# STM32G553 register map
File version: 2.0.0
CPU: CM33 r0p4, little endian, MPU, FPU, 4 interrupt priority bits
Registers are 32-bit, read-write, reset 0x0 unless marked. A register's access mark holds for its fields unless they carry their own. Offsets are from the block's base; [hi:lo] are bit positions; lines under a group give offsets from that group; 'fields as' and 'values as' point back to an identical list.

## FLASH — FLASH register block
Base 0x40022000
Same registers: FLASH_S 0x50022000
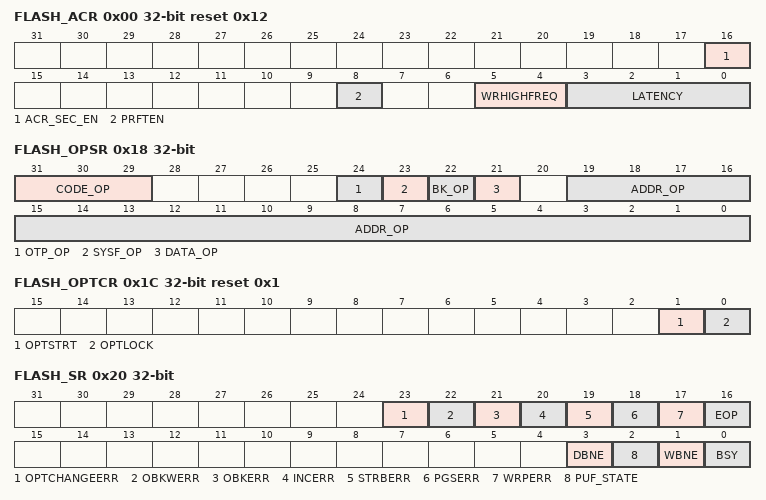
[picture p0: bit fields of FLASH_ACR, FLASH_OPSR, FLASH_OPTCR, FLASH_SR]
0x00 FLASH_ACR reset 0x12 — FLASH access control register
  [16] ACR_SEC_EN — This bit restricts the contents of the FLASH_ACR from nonsecure write access.
    0=all nonsecure access to FLASH_ACR permitted; 1=nonsecure write access to FLASH_ACR results in illegal access error. The register is read only for nonsecure code.
  [8] PRFTEN — Prefetch enable. When bit value is modified, user must read back ACR register to be sure PRFTEN has been taken into account.
    0=prefetch disabled; 1=prefetch enabled when latency is at least one wait state
  [5:4] WRHIGHFREQ — Flash signal delay
  [3:0] LATENCY — Read latency
    0=zero wait states used to read a word from nonvolatile memory; 1=one wait state used to read a word from nonvolatile memory; 2=two wait states used to read a word from nonvolatile memory; 7=seven wait states used to read a word from nonvolatile memory; 15=15 wait states used to read a word from nonvolatile memory
0x04 FLASH_KEYR wo — FLASH nonsecure key register
  [31:0] KEY — Non-volatile memory nonsecure configuration access unlock key
0x08 FLASH_SKEYR wo — FLASH secure key register
  [31:0] KEY — Non-volatile memory secure configuration access unlock key
0x0C FLASH_OPTKEYR wo — FLASH option key register
  [31:0] KEY — FLASH option bytes control access unlock key
0x10 FLASH_OBKKEYR wo — FLASH nonsecure OBK key register
  [31:0] KEY — FLASH nonsecure option bytes keys control access unlock key
0x14 FLASH_SOBKKEYR wo — FLASH secure OBK key register
  [31:0] KEY — FLASH secure option bytes keys control access unlock key
0x18 FLASH_OPSR ro reset not defined — FLASH operation status register
  [31:29] CODE_OP — Flash memory operation code
    0=No flash operation on going during previous reset; 1=Single write operation interrupted; 2=OBK alternate page erase; 3=Page erase operation interrupted; 4=Bank erase operation interrupted; 5=Mass erase operation interrupted; 6=Option change operation interrupted; 7=OBK swap page request
  [24] OTP_OP — OTP operation interrupted
  [23] SYSF_OP — Operation in system flash memory interrupted
  [22] BK_OP — Interrupted operation bank
  [21] DATA_OP — Flash high-cycle data area operation interrupted
  [19:0] ADDR_OP — Interrupted operation address
0x1C FLASH_OPTCR reset 0x1 — FLASH option control register
  [1] OPTSTRT — Option byte start change option configuration bit
  [0] OPTLOCK — FLASH_OPTCR lock option configuration bit
    0=FLASH_OPTCR register unlocked; 1=FLASH_OPTCR register locked
0x20 FLASH_SR ro (reset mask 0xFFFFFFF0) — FLASH nonsecure status register
  [23] OPTCHANGEERR — Option byte change error flag
    0=no option byte change errors occurred; 1=one or more errors occurred during an option byte change operation
  [22] OBKWERR — OBK write error flag
    0=no OBK write error occurred; 1=an OBK write error occurred
  [21] OBKERR — OBK general error flag
    0=no OBK general error occurred; 1=an OBK general error occurred
  [20] INCERR — inconsistency error flag
    0=no inconsistency error occurs; 1=a inconsistency error occurs
  [19] STRBERR — strobe error flag
    0=no strobe error occurred; 1=a strobe error occurred
  [18] PGSERR — programming sequence error flag
    0=no sequence error occurred; 1=a sequence error occurred
  [17] WRPERR — write protection error flag
    0=no write protection error occurred; 1=a write protection error occurred
  [16] EOP — end of operation flag
    0=no operation completed; 1=a operation completed
  [3] DBNE — data buffer not empty flag
    0=data buffer not used; 1=data buffer used, wait
  [2] PUF_STATE — PUF readiness
    0=PUF is not ready. Retry PUF_LAUNCH; 1=PUF is ready for use
  [1] WBNE — write buffer not empty flag
    0=write buffer empty or full; 1=write buffer waiting data to complete
  [0] BSY — busy flag
    0=no programming, erase or option byte change operation being executed; 1=programming, erase or option byte change operation being executed
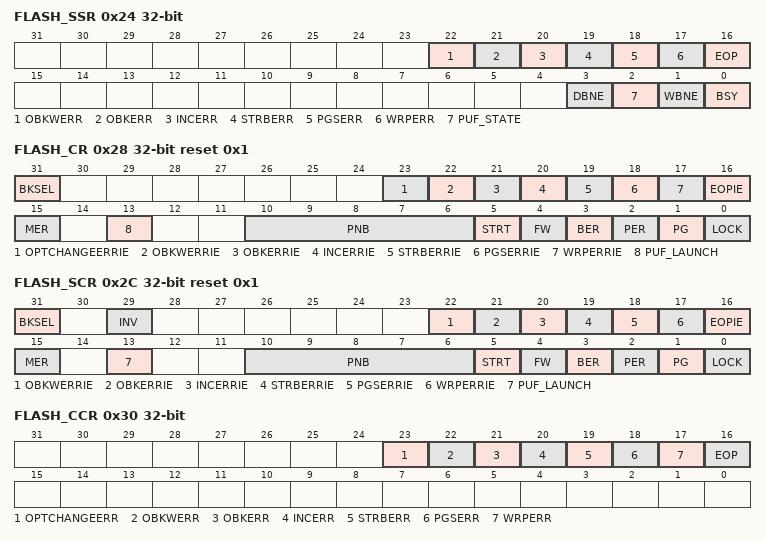
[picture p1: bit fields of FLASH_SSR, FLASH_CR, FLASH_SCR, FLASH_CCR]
0x24 FLASH_SSR ro (reset mask 0xFFFFFFF0) — FLASH secure status register
  [22] OBKWERR — OBK write error flag
    0=no OBK write error occurred; 1=an OBK write error occurred
  [21] OBKERR — OBK general error flag
    values as FLASH_SR.OBKERR
  [20] INCERR — inconsistency error flag
    0=no inconsistency error occurred; 1=a inconsistency error occurred
  [19] STRBERR — strobe error flag
    0=no strobe error occurred; 1=a strobe error occurred
  [18] PGSERR — programming sequence error flag
    0=no sequence error occurred; 1=a sequence error occurred
  [17] WRPERR — write protection error flag
    values as FLASH_SR.WRPERR
  [16] EOP — end of operation flag
    0=no operation completed; 1=a operation completed
  [3] DBNE — data buffer not empty flag
    0=data buffer not used; 1=data buffer used, wait
  [2] PUF_STATE — PUF readiness
    0=PUF is not ready. Retry PUF_LAUNCH; 1=PUF is ready for use
  [1] WBNE — write buffer not empty flag
    values as FLASH_SR.WBNE
  [0] BSY — busy flag
    values as FLASH_SR.BSY
0x28 FLASH_CR reset 0x1 — FLASH nonsecure control register
  [31] BKSEL — Bank selector bit
    0=Bank1 is selected for Bank erase / page erase / interrupt enable; 1=Bank2 is selected for BER / PER
  [23] OPTCHANGEERRIE — Option byte change error interrupt enable bit
    0=no interrupt is generated when an error occurs during an option byte change; 1=an interrupt is generated when and error occurs during an option byte change
  [22] OBKWERRIE — OBK write error interrupt enable bit
    0=no interrupt is generated on OBK write error; 1=an interrupt is generated on OBK write error
  [21] OBKERRIE — OBK general error interrupt enable bit
    0=no interrupt is generated on OBK general access error; 1=an interrupt is generated on OBK general access error
  [20] INCERRIE — inconsistency error interrupt enable bit
    0=no interrupt generated when a inconsistency error occurs; 1=interrupt generated when a inconsistency error occurs
  [19] STRBERRIE — strobe error interrupt enable bit
    0=no interrupt generated when a strobe error occurs; 1=interrupt generated when strobe error occurs
  [18] PGSERRIE — programming sequence error interrupt enable bit
    0=no interrupt generated when a sequence error occurs; 1=interrupt generated when sequence error occurs
  [17] WRPERRIE — write protection error interrupt enable bit
    0=no interrupt generated when a protection error occurs; 1=interrupt generated when a protection error occurs
  [16] EOPIE — end of operation interrupt control bit
    0=no interrupt generated at the end of operation; 1=interrupt enabled when at the end of operation
  [15] MER — Mass erase request
    0=mass erase not requested; 1=mass erase requested
  [13] PUF_LAUNCH — PUF preparation start control bit
  [10:6] PNB — page erase selection number
    0=Page 0 selected; 1=Page 1 selected; 31=Page 31 selected
  [5] STRT — erase start control bit
  [4] FW — write forcing control bit
  [3] BER — erase request
    0=bank erase not requested; 1=bank erase requested
  [2] PER — page erase request
    0=page erase not requested; 1=page erase requested
  [1] PG — programming control bit
    0=programming disabled; 1=programming enabled
  [0] LOCK — configuration lock bit
    0=FLASH_CR register unlocked; 1=FLASH_CR register locked
0x2C FLASH_SCR reset 0x1 — FLASH secure control register
  [31] BKSEL — bank selector bit
    values as FLASH_CR.BKSEL
  [29] INV — Flash memory security state invert.
  [22] OBKWERRIE — OBK write error interrupt enable bit
    values as FLASH_CR.OBKWERRIE
  [21] OBKERRIE — OBK general error interrupt enable bit
    values as FLASH_CR.OBKERRIE
  [20] INCERRIE — inconsistency error interrupt enable bit
    values as FLASH_CR.INCERRIE
  [19] STRBERRIE — strobe error interrupt enable bit
    values as FLASH_CR.STRBERRIE
  [18] PGSERRIE — programming sequence error interrupt enable bit
    values as FLASH_CR.PGSERRIE
  [17] WRPERRIE — write protection error interrupt enable bit
    values as FLASH_CR.WRPERRIE
  [16] EOPIE — end of operation interrupt control bit
    values as FLASH_CR.EOPIE
  [15] MER — mass erase request
    0=mass erase not requested; 1=mass erase requested
  [13] PUF_LAUNCH — PUF preparation start control bit
  [10:6] PNB — page erase selection number
    0=Page 0 selected; 1=Page 1 selected; 31=Page 31 selected
  [5] STRT — erase start control bit
  [4] FW — write forcing control bit
  [3] BER — erase request
    0=bank erase not requested; 1=bank erase requested
  [2] PER — page erase request
    0=page erase not requested; 1=page erase requested
  [1] PG — programming control bit
    0=programming disabled; 1=programming enabled
  [0] LOCK — configuration lock bit
    0=FLASH_SCR register unlocked; 1=FLASH_SCR register locked
0x30 FLASH_CCR wo — FLASH nonsecure clear control register
  [23] OPTCHANGEERR — Clear the flag corresponding flag in FLASH_SR by writing this bit.
  [22] OBKWERR — OBKWERR flag clear bit.
  [21] OBKERR — OBKERR flag clear bit.
  [20] INCERR — INCERR flag clear bit
  [19] STRBERR — STRBERR flag clear bit
  [18] PGSERR — PGSERR flag clear bit
  [17] WRPERR — WRPERR flag clear bit
  [16] EOP — EOP flag clear bit
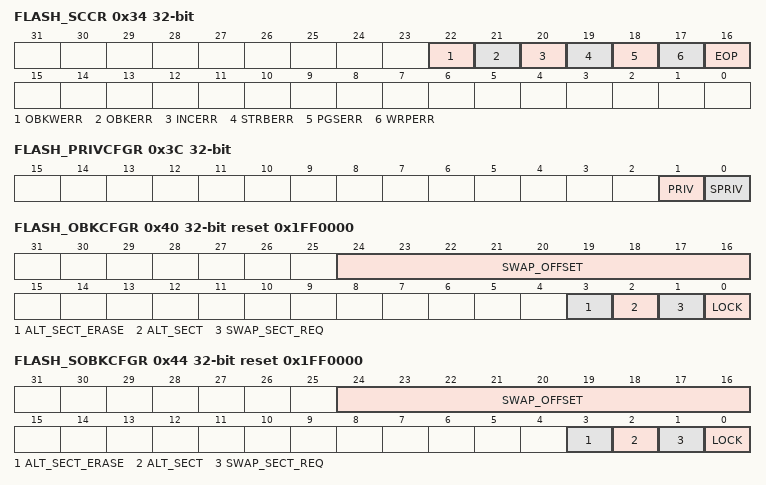
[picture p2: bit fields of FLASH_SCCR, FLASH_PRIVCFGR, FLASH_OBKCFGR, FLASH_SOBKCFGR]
0x34 FLASH_SCCR wo — FLASH secure clear control register
  [22] OBKWERR — OBKWERR flag clear bit
  [21] OBKERR — OBKWERR flag clear bit
  [20] INCERR — INCERR flag clear bit
  [19] STRBERR — STRBERR flag clear bit
  [18] PGSERR — PGSERR flag clear bit
  [17] WRPERR — WRPERR flag clear bit
  [16] EOP — EOP flag clear bit
0x3C FLASH_PRIVCFGR — FLASH privilege configuration register
  [1] PRIV — privilege attribute for non secure registers
    0=access to non secure registers is always granted; 1=access to non secure registers is denied in case of unprivileged access
  [0] SPRIV — privilege attribute for secure registers
    0=access to secure registers is always granted; 1=access to secure registers is denied in case of unprivileged access
0x40 FLASH_OBKCFGR reset 0x1FF0000 — FLASH nonsecure OBK configuration register
  [24:16] SWAP_OFFSET — Key index (offset /16 bits) pointing for next swap.
    0=means that no OBK is copied from current to alternate OBK page during SWAP operation; 0x1FF=means that all OBK data (511) are copied
  [3] ALT_SECT_ERASE — alternate page erase bit
    0=do not touch OBK page; 1=erase the alternate OBK page
  [2] ALT_SECT — alternate page bit
    0=current OBK page is mapped to OBK address range for access; 1=alternate OBK page is mapped to OBK address range for access
  [1] SWAP_SECT_REQ — OBK swap page request bit
    0=no swap requested; 1=launch the page swap
  [0] LOCK — OBKCFGR lock option configuration bit
    0=FLASH_OBKCFGR register unlocked; 1=FLASH_OBKCFGR register locked
0x44 FLASH_SOBKCFGR reset 0x1FF0000 — FLASH secure OBK configuration register
  [24:16] SWAP_OFFSET — key index (offset /16 bits) pointing for next swap.
    0=no OBK is copied from current to alternate OBK page during SWAP operation; 1=only the first OBK data (128 bits) are copied from current to alternate OBK page; 2=the two first OBK data are copied; 0x1FF=that the 511 first OBK data are copied
  [3] ALT_SECT_ERASE — alternate page erase bit
    0=do not touch OBK page; 1=erase the alternate OBK page
  [2] ALT_SECT — alternate page bit
    values as FLASH_OBKCFGR.ALT_SECT
  [1] SWAP_SECT_REQ — OBK swap page request bit
    0=no swap requested; 1=launch the page swap
  [0] LOCK — OBKCFGR lock option configuration bit
    values as FLASH_OBKCFGR.LOCK
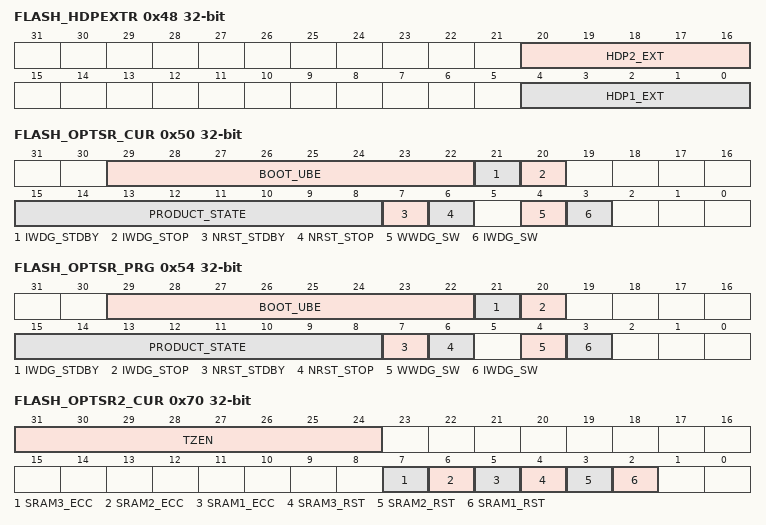
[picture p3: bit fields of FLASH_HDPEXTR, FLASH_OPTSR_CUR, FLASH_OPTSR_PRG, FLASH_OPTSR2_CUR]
0x48 FLASH_HDPEXTR — FLASH HDP extension register
  [20:16] HDP2_EXT — HDP area extension in 8Kbytes pages in Bank2. Extension is added after the END page (included).
  [4:0] HDP1_EXT — HDP area extension in 8Kbytes pages in Bank1. Extension is added after the END page (included).
0x50 FLASH_OPTSR_CUR ro reset not defined — FLASH option status register
  [29:22] BOOT_UBE — Available only on cryptography enabled devices.
    195=ST-iRoT (system flash) selected; 180=OEM-iRoT (user flash) selected. In Open PRODUCT_STATE this value selects bootloader. Default value.
  [21] IWDG_STDBY — IWDG Standby mode freeze option status bit
    0=Independent watchdog 1 frozen in Standby mode; 1=Independent watchdog 1 keep running in Standby mode
  [20] IWDG_STOP — IWDG Stop mode freeze option status bit
    0=Independent watchdog 1 frozen in system Stop mode; 1=Independent watchdog 1 keep running in system Stop mode
  [15:8] PRODUCT_STATE — Life state code (based on Hamming 8,4). See in Section201.6.11: Product state transitions.
  [7] NRST_STDBY — Core domain Standby entry reset option status bit
    0=a reset is generated when entering Standby mode on core domain; 1=no reset generated when entering Standby mode on core domain
  [6] NRST_STOP — Core domain Stop entry reset option status bit
    0=a reset is generated when entering Stop mode on core domain; 1=no reset generated when entering Stop mode on core domain
  [4] WWDG_SW — WWDG control mode option status bit
    0=WWDG watchdog is controlled by hardware; 1=WWDG watchdog is controlled by software
  [3] IWDG_SW — IWDG control mode option status bit
    0=IWDG watchdog is controlled by hardware; 1=IWDG watchdog is controlled by software
0x54 FLASH_OPTSR_PRG reset not defined — FLASH option status register
  [29:22] BOOT_UBE — Available only on cryptography enabled devices.
    195=ST-iRoT (system flash) selected; 180=OEM-iRoT (user flash) selected
  [21] IWDG_STDBY — IWDG Standby mode freeze option status bit
    0=Independent watchdog frozen in Standby mode; 1=Independent watchdog keep running in Standby mode
  [20] IWDG_STOP — IWDG Stop mode freeze option status bit
    0=Independent watchdog frozen in system Stop mode; 1=Independent watchdog keep running in system Stop mode
  [15:8] PRODUCT_STATE — Life state code (based on Hamming 8,4). See in Section201.6.11: Product state transitions.
  [7] NRST_STDBY — Core domain Standby entry reset option configuration bit
    values as FLASH_OPTSR_CUR.NRST_STDBY
  [6] NRST_STOP — Core domain Stop entry reset option configuration bit
    values as FLASH_OPTSR_CUR.NRST_STOP
  [4] WWDG_SW — WWDG control mode option configuration bit
    values as FLASH_OPTSR_CUR.WWDG_SW
  [3] IWDG_SW — IWDG control mode option configuration bit
    values as FLASH_OPTSR_CUR.IWDG_SW
0x60 FLASH_EPOCHR_CUR ro reset not defined — FLASH nonsecure EPOCH register
  [23:0] EPOCH — Non-volatile nonsecure EPOCH counter
0x64 FLASH_EPOCHR_PRG reset not defined — FLASH nonsecure EPOCH register
  [23:0] EPOCH — Non-volatile nonsecure EPOCH counter. The value programmed must be greater than the current value. Otherwise OPTCHANGEERR flag is raised.
0x68 FLASH_SEPOCHR_CUR ro reset not defined — FLASH secure EPOCH register
  [23:0] EPOCH — Non-volatile secure EPOCH counter
0x6C FLASH_SEPOCHR_PRG reset not defined — FLASH secure EPOCH register
  [23:0] EPOCH — Non-volatile secure EPOCH counter. The value programmed must be greater than the current value. Otherwise OPTCHANGEERR flag is raised.
0x70 FLASH_OPTSR2_CUR ro reset not defined — FLASH option status register 2
  [31:24] TZEN — TrustZone enable configuration bits
    195=TrustZone disabled; 180=TrustZone enabled
  [7] SRAM3_ECC — SRAM3 ECC detection and correction disable
    0=SRAM3 ECC check enabled; 1=SRAM3 ECC check disabled
  [6] SRAM2_ECC — SRAM2 ECC detection and correction disable
    0=SRAM2 ECC check enabled; 1=SRAM2 ECC check disabled
  [5] SRAM1_ECC — SRAM1 ECC detection and correction disable
    0=SRAM1 ECC check enabled; 1=SRAM1 ECC check disabled
  [4] SRAM3_RST — SRAM3 erase upon system reset
    0=SRAM3 erased when a system reset occurs; 1=SRAM3 not erased when a system reset occurs
  [3] SRAM2_RST — SRAM2 erase when system reset
    0=SRAM2 erased when a system reset occurs; 1=SRAM2 not erased when a system reset occurs
  [2] SRAM1_RST — SRAM1 erase upon system reset
    0=SRAM1 erased when a system reset occurs; 1=SRAM1 not erased when a system reset occurs
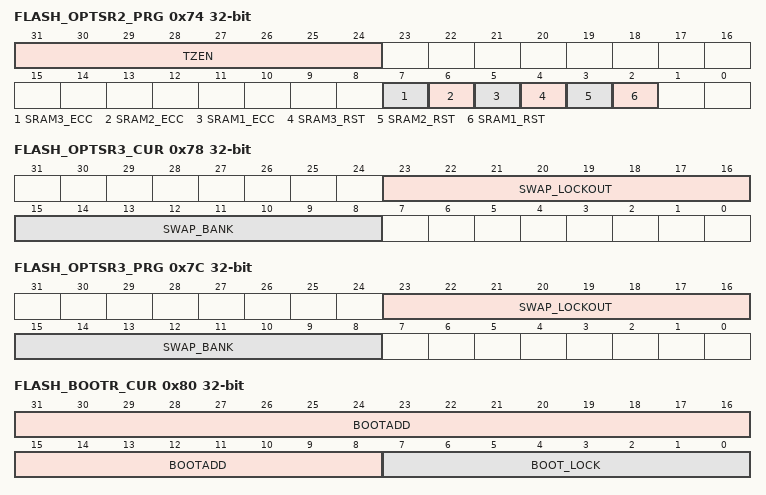
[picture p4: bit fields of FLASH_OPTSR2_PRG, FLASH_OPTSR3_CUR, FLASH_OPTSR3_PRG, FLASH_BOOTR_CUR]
0x74 FLASH_OPTSR2_PRG reset not defined — FLASH option status register 2
  fields as FLASH_OPTSR2_CUR
0x78 FLASH_OPTSR3_CUR ro reset not defined — FLASH option status register 3
  [23:16] SWAP_LOCKOUT — Configuration option specifies if the mapping of bank address space can be altered
    195=Swapping permitted; 180=Swapping disabled by configuration
  [15:8] SWAP_BANK — Configuration option specifies the mapping of bank address space after reset
    195=Default mapping, Bank1 starts first; 180=Altered mapping, Bank2 starts first
0x7C FLASH_OPTSR3_PRG reset not defined — FLASH option status register 3
  fields as FLASH_OPTSR3_CUR
0x80 FLASH_BOOTR_CUR ro reset not defined — FLASH nonsecure boot register
  [31:8] BOOTADD — Non secure unique boot entry address
  [7:0] BOOT_LOCK — Field locking the value of BOOTADD.
    195=BOOTADD can still be modified following their individual rules; 180=BOOTADD is frozen
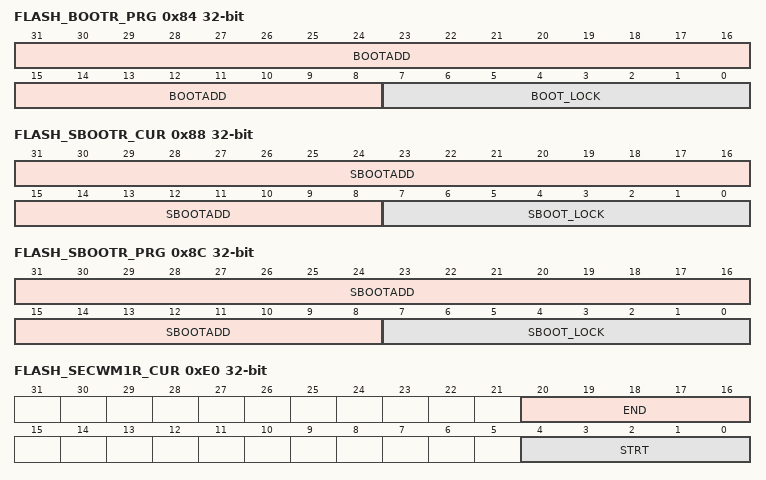
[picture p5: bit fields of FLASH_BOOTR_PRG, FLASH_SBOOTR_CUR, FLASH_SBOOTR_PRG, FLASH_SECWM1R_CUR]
0x84 FLASH_BOOTR_PRG reset not defined — FLASH nonsecure boot register
  [31:8] BOOTADD — Non secure unique boot entry address
  [7:0] BOOT_LOCK — Field locking the BOOTADD setting.
    values as FLASH_BOOTR_CUR.BOOT_LOCK
0x88 FLASH_SBOOTR_CUR ro reset not defined — FLASH secure boot register
  [31:8] SBOOTADD — Unique boot entry secure address
  [7:0] SBOOT_LOCK — Field locking the values of UBE and SBOOTADD settings.
    195=BOOT_UBE and SBOOTADD can still be modified following their individual rules; 180=BOOT_UBE and SBOOTADD are frozen
0x8C FLASH_SBOOTR_PRG reset not defined — FLASH secure boot register
  [31:8] SBOOTADD — Secure unique boot entry address.
  [7:0] SBOOT_LOCK — A field locking the values of UBE and SBOOTADD setting.
    values as FLASH_SBOOTR_CUR.SBOOT_LOCK
0x90 FLASH_OTPBLR_CUR ro reset not defined — FLASH nonsecure OTP block lock
  [31:0] LOCKBL — OTP block lock
0x94 FLASH_OTPBLR_PRG reset not defined — FLASH nonsecure OTP block lock
  [31:0] LOCKBL — OTP block lock
0x98 FLASH_BL_COM_CFG_CUR ro reset not defined — FLASH bootloader interface selection
  [31:0] BL_COM_CFG — Bootloader interface selection/configuration
0x9C FLASH_BL_COM_CFG_PRG reset not defined — FLASH bootloader interface selection
  [31:0] BL_COM_CFG — Bootloader interface selection/configuration
0xA0 FLASH_SECBB1R — FLASH secure block based registers for Bank1
  [31:0] SEC1 — Secure/nonsecure 8Kbytes flash Bank1 page attributes
    0=page (y) in Bank1 is non secure; 1=page (y) in Bank1 is secure
0xC0 FLASH_PRIVBB1R — FLASH privilege block based registers for Bank1
  [31:0] PRIV1 — Privileged/unprivileged 8-Kbyte flash Bank1 page attribute
    0=page (y) in Bank1 is unprivileged; 1=page (y) in Bank1 is privileged
0xE0 FLASH_SECWM1R_CUR ro (reset mask 0xFF00FF00) — FLASH security watermark for Bank1
  [20:16] END — Bank1 security WM area 1 end page
  [4:0] STRT — Bank1 security WM area 1 start page
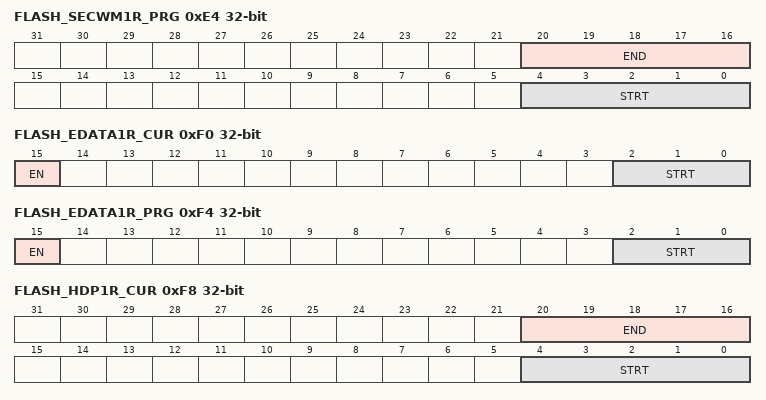
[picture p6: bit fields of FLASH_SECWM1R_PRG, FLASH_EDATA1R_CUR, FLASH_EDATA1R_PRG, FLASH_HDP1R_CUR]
0xE4 FLASH_SECWM1R_PRG (reset mask 0xFF00FF00) — FLASH security watermark for Bank1
  fields as FLASH_SECWM1R_CUR
0xE8 FLASH_WRP1R_CUR ro reset not defined — FLASH write page group protection for Bank1
  [7:0] WRPG1 — Bank1 page group protection option status byte
0xEC FLASH_WRP1R_PRG reset not defined — FLASH write page group protection for Bank1
  [7:0] WRPG1 — Bank1 page group protection option status byte
0xF0 FLASH_EDATA1R_CUR ro reset not defined — FLASH data page configuration Bank1
  [15] EN — Bank1 flash high-cycle data enable
    0=No flash high-cycle data area; 1=Flash high-cycle data is used
  [2:0] STRT — STRT contains the start pages of the flash high-cycle data area in Bank1 There is no hardware effect to those bits. They shall be managed by ST tools in Flasher.
    0=The last page of the Bank1 is reserved for flash high-cycle data; 1=The two last pages of the Bank1 are reserved for flash high-cycle data; 2=The three last pages of the Bank1 are reserved for flash high-cycle data; 7=The eight last pages of the Bank1 are reserved for flash high-cycle data
0xF4 FLASH_EDATA1R_PRG reset not defined — FLASH data page configuration Bank1
  fields as FLASH_EDATA1R_CUR
0xF8 FLASH_HDP1R_CUR ro reset not defined — FLASH HDP Bank1 configuration
  [20:16] END — HDPL barrier end set in number of 8-Kbyte pages
  [4:0] STRT — HDPL barrier start set in number of 8-Kbyte pages
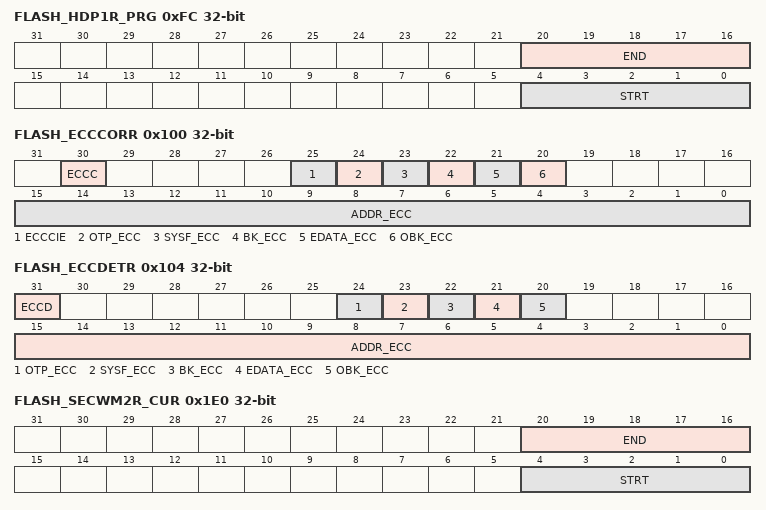
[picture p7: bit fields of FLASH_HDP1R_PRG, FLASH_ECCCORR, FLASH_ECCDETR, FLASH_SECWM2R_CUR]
0xFC FLASH_HDP1R_PRG reset not defined — FLASH HDP Bank1 configuration
  fields as FLASH_HDP1R_CUR
0x100 FLASH_ECCCORR — FLASH ECC correction register
  [30] ECCC — ECC correction set by hardware when single ECC error has been detected and corrected.
  [25] ECCCIE — ECC single correction error interrupt enable bit
    0=no interrupt generated when an ECC single correction error occurs; 1=nonsecure interrupt generated when an ECC single correction error occurs
  [24] OTP_ECC ro — OTP ECC error bit
  [23] SYSF_ECC ro — ECC fail for corrected ECC error in system flash memory
  [22] BK_ECC ro — ECC fail bank for corrected ECC error
  [21] EDATA_ECC ro — ECC fail for corrected ECC error in flash high-cycle data area
  [20] OBK_ECC ro — Single ECC error corrected in flash OB Keys storage area. It indicates the OBK storage concerned by ECC error.
  [15:0] ADDR_ECC ro — ECC error address
0x104 FLASH_ECCDETR — FLASH ECC detection register
  [31] ECCD — ECC detection
  [24] OTP_ECC ro — OTP ECC error bit
  [23] SYSF_ECC ro — ECC fail for double ECC error in system flash memory
  [22] BK_ECC ro — ECC fail bank for double ECC error
  [21] EDATA_ECC ro — ECC fail double ECC error in flash high-cycle data area
  [20] OBK_ECC ro — ECC fail double ECC error in flash OB Keys storage area. It indicates the OBK storage concerned by ECC error.
  [15:0] ADDR_ECC ro — ECC error address
0x108 FLASH_ECCDR ro — FLASH ECC data
  [15:0] DATA_ECC — ECC error data
0x1A0 FLASH_SECBB2R — FLASH secure block-based registers for Bank2
  [31:0] SEC2 — Secure/nonsecure flash Bank2 page attribute
    0=page (y) in Bank2 is non secure; 1=page (y) in Bank2 is secure
0x1C0 FLASH_PRIVBB2R — FLASH privilege block-based registers for Bank2
  [31:0] PRIV2 — Privileged / non-privileged 8-Kbyte flash Bank2 page attribute
    0=page (y) in Bank2 is unprivileged; 1=page (y) in Bank2 is privileged
0x1E0 FLASH_SECWM2R_CUR ro (reset mask 0xFF00FF00) — FLASH security watermark for Bank2
  [20:16] END — Bank2 security WM end page
  [4:0] STRT — Bank2 security WM area start page
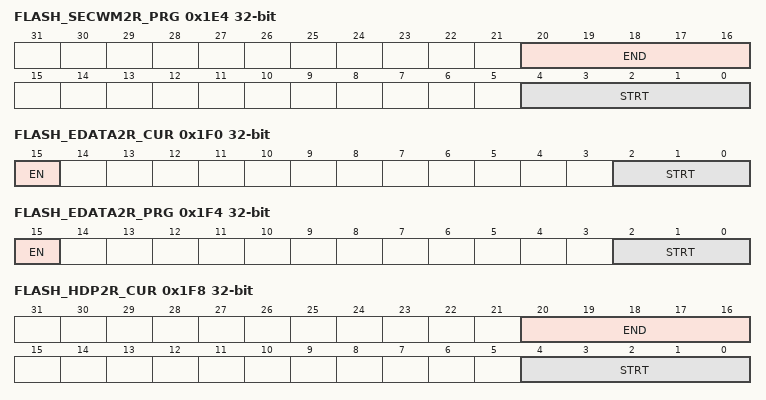
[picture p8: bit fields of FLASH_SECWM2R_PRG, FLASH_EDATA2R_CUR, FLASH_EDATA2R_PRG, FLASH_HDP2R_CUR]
0x1E4 FLASH_SECWM2R_PRG (reset mask 0xFF00FF00) — FLASH security watermark for Bank2
  fields as FLASH_SECWM2R_CUR
0x1E8 FLASH_WRP2R_CUR ro reset not defined — FLASH write page group protection for Bank2
  [7:0] WRPG2 — Bank2 page group protection option status byte
0x1EC FLASH_WRP2R_PRG reset not defined — FLASH write page group protection for Bank2
  [7:0] WRPG2 — Bank2 page group protection option status byte
0x1F0 FLASH_EDATA2R_CUR ro reset not defined — FLASH data page configuration Bank2
  [15] EN — Bank2 flash high-cycle data enable
    values as FLASH_EDATA1R_CUR.EN
  [2:0] STRT — STRT contains the start pages of the flash high-cycle data area in Bank2 There is no hardware effect to those bits. They shall be managed by ST tools in Flasher.
    0=The last page of the Bank2is reserved for flash high-cycle data; 1=The two last pages of the Bank2 are reserved for flash high-cycle data; 2=The three last pages of the Bank2 are reserved for flash high-cycle data; 7=The eight last pages of the Bank2 are reserved for flash high-cycle data
0x1F4 FLASH_EDATA2R_PRG reset not defined — FLASH data page configuration Bank2
  [15] EN — Bank2 flash high-cycle data enable
    values as FLASH_EDATA1R_CUR.EN
  [2:0] STRT — STRT contains the start pages of the flash high-cycle data area in Bank2 There is no hardware effect to those bits. They shall be managed by ST tools in Flasher.
    0=The last page of the Bank2 is reserved for flash high-cycle data; 1=The two last pages of the Bank2 are reserved for flash high-cycle data; 2=The three last pages of the Bank2 are reserved for flash high-cycle data; 7=The eight last pages of the Bank2 are reserved for flash high-cycle data
0x1F8 FLASH_HDP2R_CUR ro reset not defined — FLASH HDP Bank2 configuration
  fields as FLASH_HDP1R_CUR
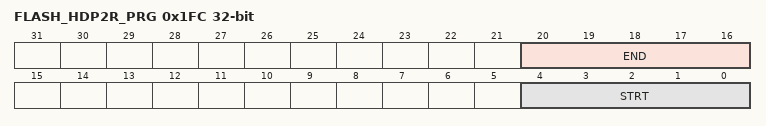
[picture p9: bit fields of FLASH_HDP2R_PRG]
0x1FC FLASH_HDP2R_PRG reset not defined — FLASH HDP Bank2 configuration
  fields as FLASH_HDP1R_CUR
